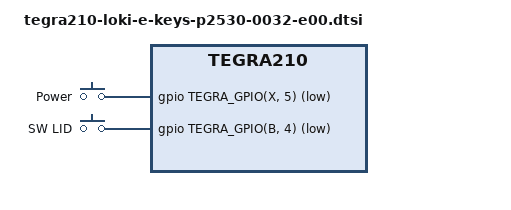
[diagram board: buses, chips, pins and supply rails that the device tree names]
#include <dt-bindings/gpio/tegra-gpio.h>
#include <dt-bindings/input/input.h>

/ {
	gpio-keys {
		compatible = "gpio-keys";
		gpio-keys,name = "gpio-keys";
		status = "okay";
		disable-on-recovery-kernel;

		power {
			label = "Power";
			gpios = <&gpio TEGRA_GPIO(X, 5) GPIO_ACTIVE_LOW>;
			linux,code = <KEY_POWER>;
			gpio-key,wakeup;
			debounce-interval = <30>;
		};

		sw_lid {
			label = "SW LID";
			gpios = <&gpio TEGRA_GPIO(B, 4) GPIO_ACTIVE_LOW>;
			linux,code = <SW_LID>;
			linux,input-type = <EV_SW>;
			gpio-key,wakeup;
			debounce-interval = <300>;
		};
	};

	gpio-timed-keys {
		compatible = "gpio-timed-keys";
		gpio-keys,name = "gpio-timed-keys";
		status = "disabled";
		enable-on-recovery-kernel;

		power {
			label = "Power";
			gpios = <&gpio TEGRA_GPIO(X, 5) GPIO_ACTIVE_LOW>;
			linux,num_codes = <3>;
			linux,press-time-secs = <1 3 5>;
			linux,key-codes = <KEY_DOWN KEY_DISPLAYTOGGLE KEY_ENTER>;
			gpio-key,wakeup;
		};
	};
};
